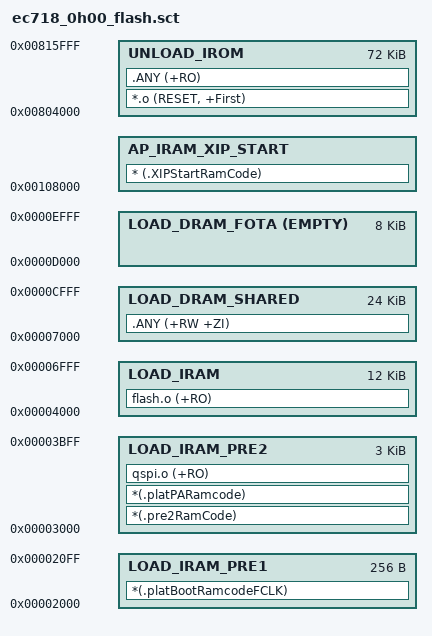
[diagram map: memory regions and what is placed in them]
#! armcc -E

LR_IROM1 0x00804000 0x12000  {    ; load region size_region
  UNLOAD_IROM 0x00804000 0x12000  {  ; load address = execution address
   *.o (RESET, +First)
   .ANY (+RO)
  }

  AP_IRAM_XIP_START 0x00108000 ALIGN 32 {  ; RW data
  * (.XIPStartRamCode)
  }

  LOAD_IRAM_PRE1 0x00002000 0x000100  {  ; code in ram
  *(.platBootRamcodeFCLK)
    }
    
  LOAD_IRAM_PRE2 0x00003000 0x000c00  {  ; code in ram
  *(.pre2RamCode)
  *(.platPARamcode)
    qspi.o (+RO)
    }
  
  LOAD_IRAM 0x00004000 0x003000  {  ; code in ram
  flash.o (+RO)
  }
  
  LOAD_DRAM_SHARED 0x00007000 0x006000  {  ; RW data
  .ANY (+RW +ZI)
  }
  
  LOAD_DRAM_FOTA 0x000d000 EMPTY 0x002000  {  ; RW data
  }
}

